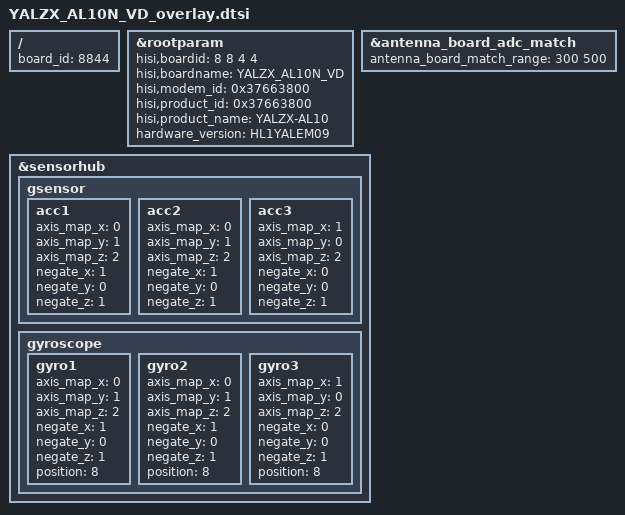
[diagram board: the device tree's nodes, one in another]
/**
 * Copyright (C) 2014 Hisilicon Ltd.
 *
 *  This program is free software; you can redistribute it and/or modify
 *  it under the terms of the GNU General Public License version 2 as
 *  publishhed by the Free Software Foundation.
 */

/include/ "YALZX_AL10N_VC_overlay.dtsi"

/ {
	board_id = <8844>;
};

	&rootparam{
		hisi,boardid = <8 8 4 4>;
		hisi,boardname = "YALZX_AL10N_VD";
		hisi,modem_id = <0x37663800>;
		hisi,product_id = <0x37663800>;
		hisi,product_name = "YALZX-AL10";
		hardware_version = "HL1YALEM09";
	};

	&antenna_board_adc_match {
		antenna_board_match_range = <300 500>;
	};
	&sensorhub {
		gsensor {
			acc1 {
				axis_map_x = <0>;
				axis_map_y = <1>;
				axis_map_z = <2>;
				negate_x = <1>;
				negate_y = <0>;
				negate_z = <1>;
			};
			acc2 {
				axis_map_x = <0>;
				axis_map_y = <1>;
				axis_map_z = <2>;
				negate_x = <1>;
				negate_y = <0>;
				negate_z = <1>;
			};
			acc3 {
				axis_map_x = <1>;
				axis_map_y = <0>;
				axis_map_z = <2>;
				negate_x = <0>;
				negate_y = <0>;
				negate_z = <1>;
			};
		};

		gyroscope {
			gyro1 {
				axis_map_x = <0>;
				axis_map_y = <1>;
				axis_map_z = <2>;
				negate_x = <1>;
				negate_y = <0>;
				negate_z = <1>;
				position = <8>;
			};
			gyro2 {
				axis_map_x = <0>;
				axis_map_y = <1>;
				axis_map_z = <2>;
				negate_x = <1>;
				negate_y = <0>;
				negate_z = <1>;
				position = <8>;
			};
			gyro3 {
				axis_map_x = <1>;
				axis_map_y = <0>;
				axis_map_z = <2>;
				negate_x = <0>;
				negate_y = <0>;
				negate_z = <1>;
				position = <8>;
			};
		};
	};
